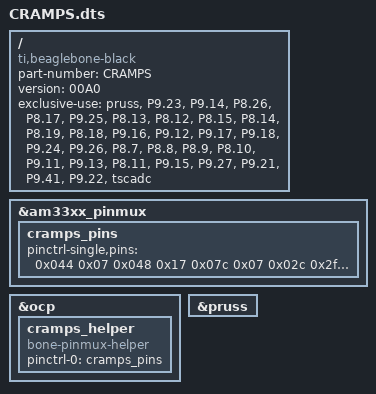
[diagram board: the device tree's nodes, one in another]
// This DTS overlay sets the required pins for CRAMPS
// Some lines are commented out, and should be uncommented for added functionality.
// This file is based off a dts by hzeller at https://github.com/hzeller/beagleg/blob/master/hardware/CRAMPS/BeagleG-CRAMPS.dts

// This file can be saved wherever with the -o option, but it is recommended to use /lib/firmware.

// Compile with dtc -O dtb -I dts -o /lib/firmware/CRAMPS.dtbo -b 0 -@ CRAMPS.dts
// Dynamically load with echo CRAMPS > /sys/devices/bone_capemgr.?/slots

/dts-v1/;
/plugin/;

/ {
	// Only compatible with beaglebone black
	compatible = "ti,beaglebone-black";

	// Part number. Used for loading with capemgr (depreciated).
	part-number = "CRAMPS";

	// Version can be used to test changes. Note that this should be changed in the Makefile as this needs to match with the name.
	version = "00A0";

	// Tell linux we want exclusive control over these pins.
	exclusive-use =
	// PRUs
		"pruss",
	// Power and Control
	//	MachPwr  AxisEnbl E-Out    E-Stop   DBG_LED
		"P9.23", "P9.14", "P8.26", "P8.17", "P9.25",
	// Step and Direction
	//	X:stp     dir     Y:stp    dir      Z:stp     dir
		"P8.13", "P8.12", "P8.15", "P8.14", "P8.19", "P8.18",
	//  E0:stp    dir     E1:stp   dir      E2:stp    dir
		"P9.16", "P9.12", "P9.17", "P9.18", "P9.24", "P9.26",
	// End Stops
	//	X-max   X-min   Y-max   Y-min    Z-max    Z-min
		"P8.7", "P8.8", "P8.9", "P8.10", "P9.11", "P9.13",
	// FETs
	//	1:       2:       3:       4:       5:       6:
		"P8.11", "P9.15", "P9.27", "P9.21", "P9.41", "P9.22",
	// Analog digital converter
		"tscadc";

	// Configure the pins.
	fragment@0 {
		target = <&am33xx_pinmux>;
		__overlay__ {
			cramps_pins: cramps_pins {
				pinctrl-single,pins = <
				// Power and Control
					0x044 0x07	/* P9.23  GPIO1[17] out, pd  machine_pwr MACHINE_PWR */
					0x048 0x17	/* P9.14  GPIO1[18] out, pu  ~axis_ena	MOTOR_ENABLE */
					0x07c 0x07	/* P8.26  GPIO1[29] out, pd  estop_sw	ESTOP_SW */
					0x02c 0x2f	/* P8.17  GPIO0[27] in       estop		ESTOP */
				// Step and Direction
					0x024 0x07	/* P8.13  GPIO0[23] out, pd  x_step		MOTOR_1_STEP */
					0x030 0x07	/* P8.12  GPIO1[12] out, pd  x_dir		MOTOR_1_DIR */
					0x03c 0x07	/* P8.15  GPIO1[15] out, pd  y_step		MOTOR_2_STEP */
					0x028 0x07	/* P8.14  GPIO0[26] out, pd  y_dir		MOTOR_2_DIR */
					0x020 0x07	/* P8.19  GPIO0[22] out, pd  z_step		MOTOR_3_STEP */
					0x08c 0x07	/* P8.18  GPIO2[1]  out, pd  z_dir		MOTOR_3_DIR */
					0x04c 0x07	/* P9.16  GPIO1[19] out, pd  e0_step	MOTOR_4_STEP */
					0x078 0x07	/* P9.12  GPIO1[28] out, pd  e0_dir		MOTOR_4_DIR */
					0x15c 0x07	/* P9.17  GPIO0[5]  out, pd  e1_step	MOTOR_5_STEP */
					0x158 0x07	/* P9.18  GPIO0[4]  out, pd  e1_dir		MOTOR_5_DIR */
					0x184 0x07	/* P9.24  GPIO0[15] out, pd  e2_step	MOTOR_6_STEP */
					0x180 0x07	/* P9.26  GPIO0[14] out, pd  e2_dir		MOTOR_6_DIR */
				// End Stops
					0x094 0x2f	/* P8.8   GPIO2[3]  in       x-min		END_X_MIN */
					0x090 0x2f	/* P8.7   GPIO2[2]  in       x-max		END_X_MAX */
					0x098 0x2f	/* P8.10  GPIO2[4]  in       y-min		END_Y_MIN */
					0x09c 0x2f	/* P8.9   GPIO2[5]  in       y-max		END_Y_MAX */
		 			0x074 0x2f	/* P9.13  GPIO0[31] in       z-min		END_Z_MIN */
					0x070 0x2f	/* P9.11  GPIO0[30] in       z-max		END_Z_MAX */
				// FETs
					0x034 0x07	/* P8.11  GPIO1[13] out, pd  fet1 */
					0x040 0x07	/* P9.15  GPIO1[16] out, pd  fet2 */
					0x1a4 0x07	/* P9.27  GPIO3[19] out, pd  fet3 */
					0x154 0x07	/* P9.21  GPIO0[3]  out, pd  fet4 */
					0x1b4 0x07	/* P9.41A GPIO0[20] out, pd  fet5 */
					0x150 0x07	/* P9.22  GPIO0[2]  out, pd  fet6 */
				>;
			};
		};
	};

	// Enable the previous pins and assign them to the On Chip Periprial driver.
	fragment@1{
		target = <&ocp>;
		__overlay__ {
			cramps_helper: cramps_helper {
				compatible = "bone-pinmux-helper";
				pinctrl-names = "default";
				pinctrl-0 = <&cramps_pins>;
				status = "okay";
			};
		};
	};

	// Turn on the PRUs
	fragment@2{
		target = <&pruss>;
		__overlay__ {
			status = "okay";
		};
	};
};
